# haltium_secure register map
Vendor: Nordic Semiconductor; Series: nRFHaltium; File version: 1
CPU: CM33 r0p4, little endian, MPU, FPU, 3 interrupt priority bits, 480 interrupts
Registers are 32-bit, read-write, reset 0x0 unless marked. A register's access mark holds for its fields unless they carry their own. Offsets are from the block's base; [hi:lo] are bit positions; lines under a group give offsets from that group; {n}, {i} and the like mark numbered series.

## GLRC2_S — LRC 0
Base 0xBF006000
Same registers: LRC0_S 0x5100E000, LRC1_S 0x5101E000
{0x0+4i} TASKS_CLKSTART[{i}] (i=0..7) wo — Description collection: Start the clock source [n]
  [0] TASKS_CLKSTART — Start the clock source [n]
    1=Trigger task
{0x20+4i} TASKS_CLKSTOP[{i}] (i=0..7) wo — Description collection: Clear the TASKS_CLKSTART[n] request
  [0] TASKS_CLKSTOP — Clear the TASKS_CLKSTART[n] request
    1=Trigger task
0x40 TASKS_CONSTLAT wo — Enable constant latency mode
  [0] TASKS_CONSTLAT
    1=Trigger task
0x44 TASKS_LOWPWR wo — Enable Low Power mode
  [0] TASKS_LOWPWR
    1=Trigger task
{0x100+4i} EVENTS_CLKSTARTED[{i}] (i=0..7) — Description collection: Clock [n] started
  [0] EVENTS_CLKSTARTED — Clock [n] started
    0=NotGenerated (Event not generated); 1=Generated (Event generated)
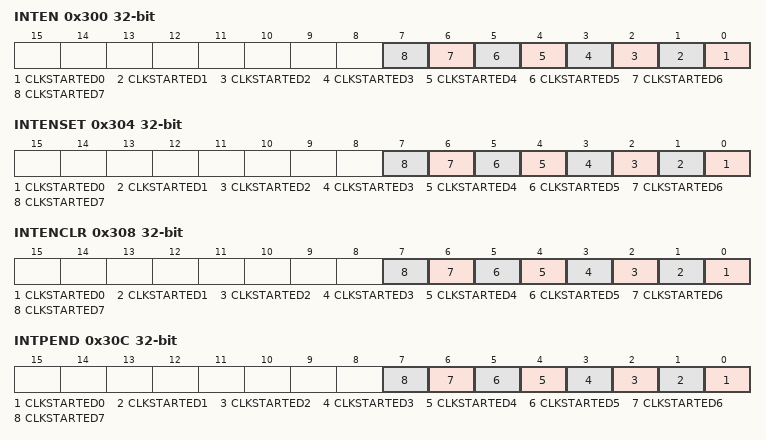
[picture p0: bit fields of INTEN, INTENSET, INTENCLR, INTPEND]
0x300 INTEN — Enable or disable interrupt
  [all] fields
    0=Disabled; 1=Enabled
  [n] CLKSTARTED{n} (n=0..7) — Enable or disable interrupt for event CLKSTARTED[{n}]
0x304 INTENSET — Enable interrupt
  [all] fields
    on read: 0=Disabled (Read: Disabled); 1=Enabled (Read: Enabled) | on write: 1=Set (Enable)
  [n] CLKSTARTED{n} (n=0..7) — Write '1' to enable interrupt for event CLKSTARTED[{n}]
0x308 INTENCLR — Disable interrupt
  [all] fields
    on read: 0=Disabled (Read: Disabled); 1=Enabled (Read: Enabled) | on write: 1=Clear (Disable)
  [n] CLKSTARTED{n} (n=0..7) — Write '1' to disable interrupt for event CLKSTARTED[{n}]
0x30C INTPEND ro — Pending interrupts
  [all] fields
    on read: 0=NotPending (Read: Not pending); 1=Pending (Read: Pending)
  [n] CLKSTARTED{n} (n=0..7) — Read pending status of interrupt for event CLKSTARTED[{n}]
{0x400+8i} CLKSTAT[{i}] (i=0..7) group — Unspecified
  0x00 RUN — Description cluster: Status indicating that TASKS_START task has been triggered for clock [n]
    [0] STATUS — Clock start task triggered or not
      0=NotTriggered (Task not triggered); 1=Triggered (Task triggered)
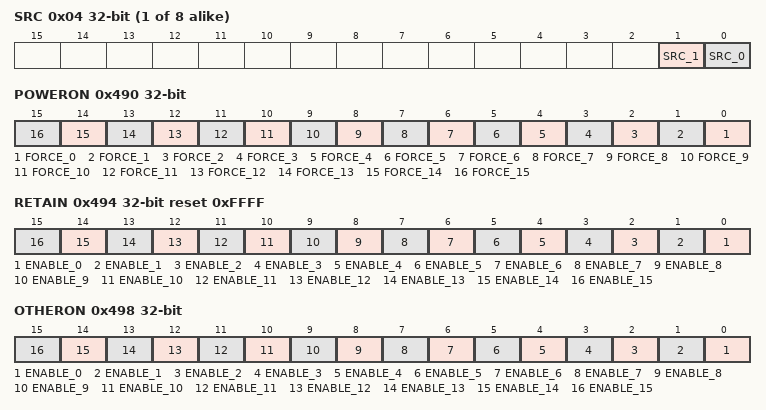
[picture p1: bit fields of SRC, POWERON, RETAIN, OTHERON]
  0x04 SRC — Description cluster: Status indicating which clock source is running for clock [n]
    [1] SRC_1 — Clock source
    [0] SRC_0 — Clock source
{0x440+8i} CLKCTRL[{i}] (i=0..7) group — Unspecified
  0x00 ALWAYSRUN — Description cluster: Force the clock source [n] and tree running always
    [0] FORCE — Force the clock always running
      0=Automatic clock control enabled; 1=AlwaysRun (Clock always running)
  0x04 SRC — Description cluster: Select the clock source for clock [n]
    [1] SRC_1 — Clock source
    [0] SRC_0 — Clock source
0x480 CONSTLATSTAT — Status of constant latency
  [0] STATUS
    0=Low power enabled; 1=ConstLat (Constant latency enabled)
0x490 POWERON — Force power domain ON
  [all] fields
    0=Automatic power control enabled; 1=AlwaysOn (Keep the power domain ON to the domain even though there is no request)
  [n] FORCE_{n} (n=0..15) — Force the power domain ON for domain[{n}]
0x494 RETAIN reset 0xFFFF — Retain power domain
  [all] fields
    0=Disable (Retain disabled); 1=Enable (retain enabled)
  [n] ENABLE_{n} (n=0..15) — Retain the power domain on for domain[{n}]
0x498 OTHERON — Request other domain ON
  [all] fields
    0=Automatic power control enabled; 1=AlwaysOn (Request to keep the other power domain ON to the domain even though there is no request)
  [n] ENABLE_{n} (n=0..15) — Request power domain ON for other domain[{n}]

## GMEMCONF2_S — Memory configuration 0
Base 0xBF009000
Same registers: MEMCONF_NS 0x41012000, MEMCONF_S 0x51012000
{0x500+0x10*i} POWER[{i}] (i=0..3) group — Unspecified
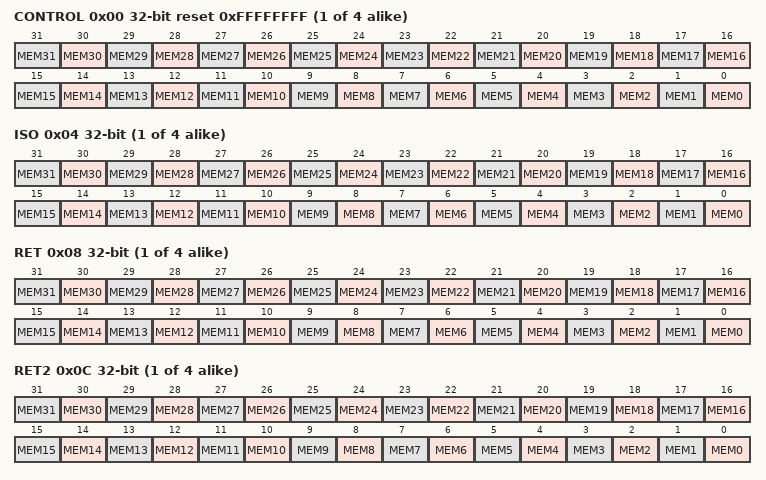
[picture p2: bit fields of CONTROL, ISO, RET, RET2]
  0x00 CONTROL reset 0xFFFFFFFF — Description cluster: RAM/ROM[n] power control register.
    [all] fields
      0=Off (Power down); 1=On (Power up)
    [n] MEM{n} (n=0..31) — Keep the RAM/ROM block MEM[{n}] on or off when in System ON mode.
  0x04 ISO — Description cluster: RAM/ROM [n] power isolation control register.
    [all] fields
      0=Off (Isolation off); 1=On (Isolation on)
    [n] MEM{n} (n=0..31) — Turn on/off the power isolation for RAM/ROM block MEM[{n}].
  0x08 RET — Description cluster: RAM retention for RAM/ROM [n].
    [all] fields
      0=Off (Retention off); 1=On (Retention on)
    [n] MEM{n} (n=0..31) — Keep the RAM block MEM[{n}] retained when in System OFF mode.
  0x0C RET2 — Description cluster: RAM retention for the second bank in the RAM block
    [all] fields
      0=Off (Retention off); 1=On (Retention on)
    [n] MEM{n} (n=0..31) — Keep the second bank in RAM block MEM[{n}] retained when in System OFF mode.
{0x600+0x18*i} REPAIR[{i}] (i=0..31) group — Unspecified
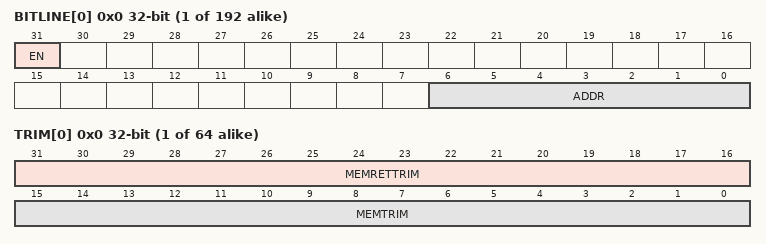
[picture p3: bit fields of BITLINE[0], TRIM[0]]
  {0x0+4j} BITLINE[{j}] (j=0..5) — Description collection: RAM repair bitline configuration RAM/ROM blocks.
    [31] EN — Enable bitline repair
      0=Disabled (Repair disabled.); 1=Enabled (Repair enabled.)
    [6:0] ADDR — Repair address of the bitline
0x900 BLOCKTYPE group — Unspecified
  {0x0+4j} TRIM[{j}] (j=0..63) — Description collection: Trim configuration for the RAM/ROM block types.
    [31:16] MEMRETTRIM — Trimming for retention mode for decreased leakage. Must be kept active in RAM retention mode.
    [15:0] MEMTRIM — Read/write margin trim.
